# STM32L4R7xx register map
File version: 1.0
Registers are 32-bit, read-write, reset 0x0 unless marked. A register's access mark holds for its fields unless they carry their own. Offsets are from the block's base; [hi:lo] are bit positions; {n}, {i} and the like mark numbered series.

## OPAMP2 — Operational Amplifier (OPAMP)
Base 0x40007810
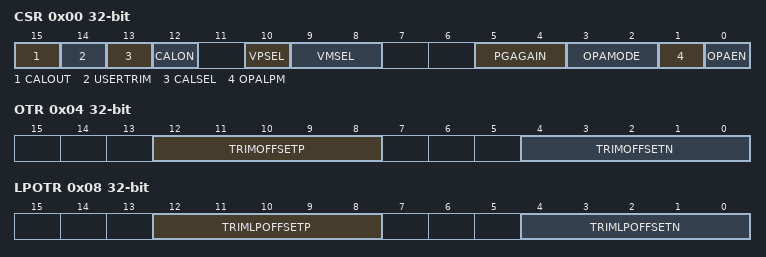
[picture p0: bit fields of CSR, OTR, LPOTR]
0x00 CSR — OPAMP control/status register
  [15] CALOUT — Operational amplifier2 calibration output
  [14] USERTRIM — User trimming enable
  [13] CALSEL — Calibration selection
  [12] CALON — Calibration mode enable
  [10] VPSEL — Non inverted input selection
  [9:8] VMSEL — Inverting input selection
  [5:4] PGAGAIN — Operational amplifier2 Programmable amplifier gain value
  [3:2] OPAMODE — Operational amplifier2 PGA mode
  [1] OPALPM — Operational amplifier2 Low Power Mode
  [0] OPAEN — Operational amplifier2 Enable
0x04 OTR — OPAMP
  [12:8] TRIMOFFSETP — Trim for PMOS differential pairs
  [4:0] TRIMOFFSETN — Trim for NMOS differential pairs
0x08 LPOTR — OPAMP
  [12:8] TRIMLPOFFSETP — Trim for PMOS differential pairs
  [4:0] TRIMLPOFFSETN — Trim for NMOS differential pairs

## SYSCFG — System configuration controller
Base 0x40010000
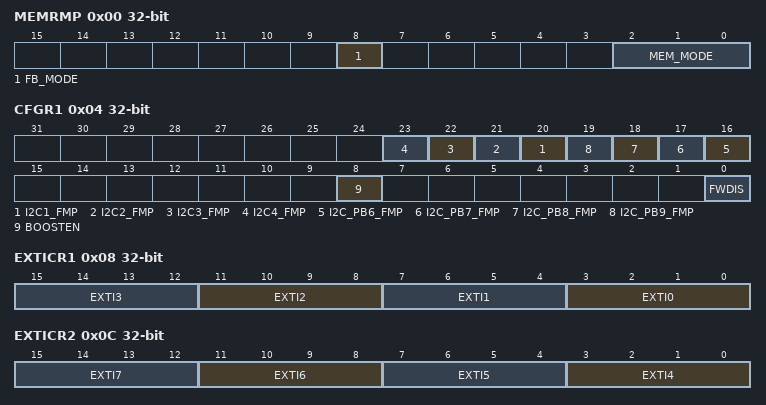
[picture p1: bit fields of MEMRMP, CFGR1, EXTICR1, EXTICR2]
0x00 MEMRMP — SYSCFG memory remap register
  [8] FB_MODE — Flash Bank mode selection
    0=BANK1; 1=BANK2
  [2:0] MEM_MODE — SYSCFG_Memory Remap Config
    0=FLASH (Main Flash memory mapped at 0x00000000); 1=SYSTEMFLASH (System Flash memory mapped at 0x00000000); 3=SRAM (SRAM1 mapped at 0x00000000); 2=FMC (FMC bank 1 (NOR/PSRAM 1 and 2) mapped at 0x00000000); 6=QUADSPI (QUADSPI memory mapped at 0x00000000)
0x04 CFGR1 — SYSCFG configuration register 1
  [n+19] I2C{n}_FMP (n=1..4) — I2C{n} Fast mode plus
  [n+10] I2C_PB{n}_FMP (n=6..9) — I2C PB{n} Fast mode plus
  [8] BOOSTEN — I/O analog switch voltage booster enable
  [0] FWDIS — FIREWALL access enable
0x08 EXTICR1 — SYSCFG external interrupt configuration registers
  [4n+3:4n] EXTI{n} (n=0..3) — EXTI {n} configuration
0x0C EXTICR2 — SYSCFG external interrupt configuration registers
  [4n-13:4n-16] EXTI{n} (n=4..7) — EXTI {n} configuration
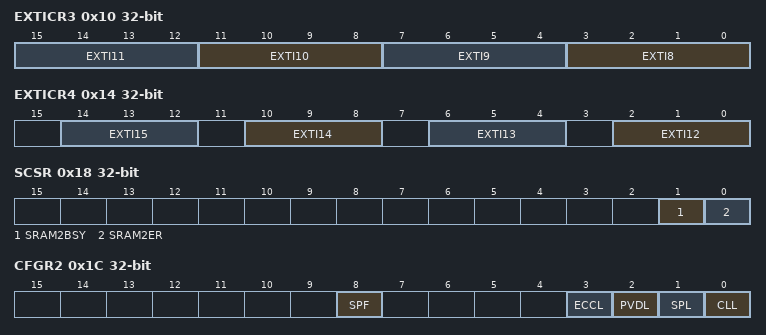
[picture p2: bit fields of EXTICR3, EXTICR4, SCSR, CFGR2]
0x10 EXTICR3 — SYSCFG external interrupt configuration registers
  [4n-29:4n-32] EXTI{n} (n=8..11) — EXTI {n} configuration
0x14 EXTICR4 — SYSCFG external interrupt configuration registers
  [4n-46:4n-48] EXTI{n} (n=12..15) — EXTI {n} configuration
0x18 SCSR — SYSCFG SRAM2 control and status register
  [1] SRAM2BSY — SRAM2 Erase Ongoing
  [0] SRAM2ER — SRAM2 Erase Request
0x1C CFGR2 — SYSCFG configuration register 2
  [8] SPF — SRAM Parity Flag
  [3] ECCL — ECC Lock
  [2] PVDL — PVD Lock
  [1] SPL — SRAM Parity Lock
  [0] CLL — Core Lockup Lock
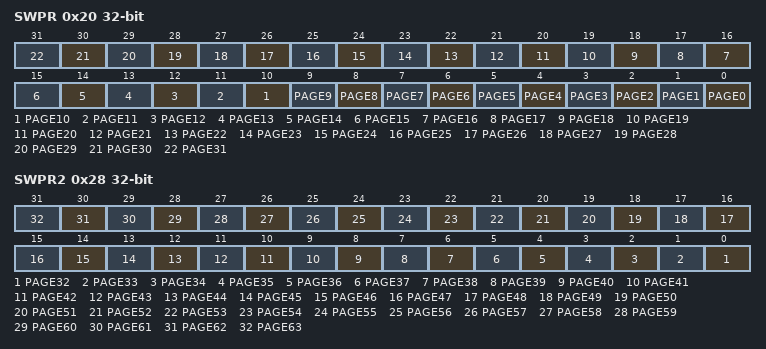
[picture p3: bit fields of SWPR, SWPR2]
0x20 SWPR — SYSCFG SRAM2 write protection register
  [n] PAGE{n} (n=0..31) — SRAM2 Write protection page {n}
0x24 SKR — SYSCFG SRAM2 key register
  [7:0] KEY — SRAM2 write protection key for software erase
0x28 SWPR2 — SYSCFG SRAM2 write protection register 2
  [n-32] PAGE{n} (n=32..63) — SRAM2 Write protection page {n}

## VREFBUF
Base 0x40010030
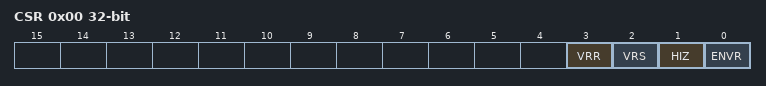
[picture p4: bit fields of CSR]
0x00 CSR — VREFBUF control and status register
  [3] VRR — Voltage reference buffer ready
  [2] VRS — Voltage reference scale
    0=SCALE0 (Voltage reference scale 0 (VREF_OUT1)); 1=SCALE1 (Voltage reference scale 1 (VREF_OUT2))
  [1] HIZ — High impedance mode
  [0] ENVR — Voltage reference buffer enable
0x04 CCR — VREFBUF calibration and control register
  [5:0] TRIM — TRIM[5:0] bits (Trimming code)

## COMP1 — Comparator
Base 0x40010200
Same registers: COMP2 0x40010204 (alternate view of COMP12_COMMON)
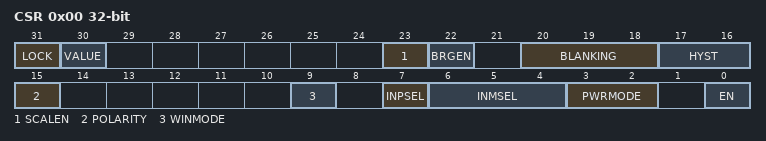
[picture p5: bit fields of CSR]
0x00 CSR — COMP control and status register
  [31] LOCK — Comparator lock
  [30] VALUE — Comparator output level
  [23] SCALEN — Comparator scaler bridge enable
  [22] BRGEN — Comparator voltage scaler enable
  [20:18] BLANKING — Comparator blanking source
    0=NONE (Comparator output without blanking); 1=TIM1_OC5_COMP1 (Comparator output blanking source TIM1 OC5 (specific to COMP instance: COMP1)); 2=TIM2_OC3_COMP1 (Comparator output blanking source TIM2 OC3 (specific to COMP instance: COMP1)); 4=TIM3_OC3_COMP1 (Comparator output blanking source TIM3 OC3 (specific to COMP instance: COMP1))
  [17:16] HYST — Comparator hysteresis
    0=NONE (No hysteresis); 1=LOW (Hysteresis level low); 2=MEDIUM (Hysteresis level medium); 3=HIGH (Hysteresis level high)
  [15] POLARITY — Comparator output polarity
    0=NONINVERTED (COMP output polarity is not inverted: comparator output is high when the plus (non-inverting) input is at a higher voltage than the minus (inverting) input); 1=INVERTED (COMP output polarity is inverted: comparator output is low when the plus (non-inverting) input is at a lower voltage than the minus (inverting) input)
  [9] WINMODE — Pair of comparators window mode. Bit intended to be used with COMP common instance (COMP_Common_TypeDef)
    0=DISABLE (Window mode disable: Comparators 1 and 2 are independent); 1=COMP1_INPUT_PLUS_COMMON (Window mode enable: Comparators instances pair COMP1 and COMP2 have their input plus connected together. The common input is COMP1 input plus (COMP2 input plus is no more accessible).)
  [7] INPSEL — Comparator input plus selection
    0=IO1 (Comparator input plus connected to IO1 (pin PC5 for COMP1, pin PB4 for COMP2)); 1=IO2 (Comparator input plus connected to IO2 (pin PB2 for COMP1, pin PB6 for COMP2))
  [6:4] INMSEL — Comparator input minus selection
  [3:2] PWRMODE — Comparator power mode
    0=HIGHSPEED (COMP power mode to high speed); 1=MEDIUMSPEED (COMP power mode to medium speed); 3=ULTRALOWPOWER (COMP power mode to ultra-low power)
  [0] EN — Comparator enable
